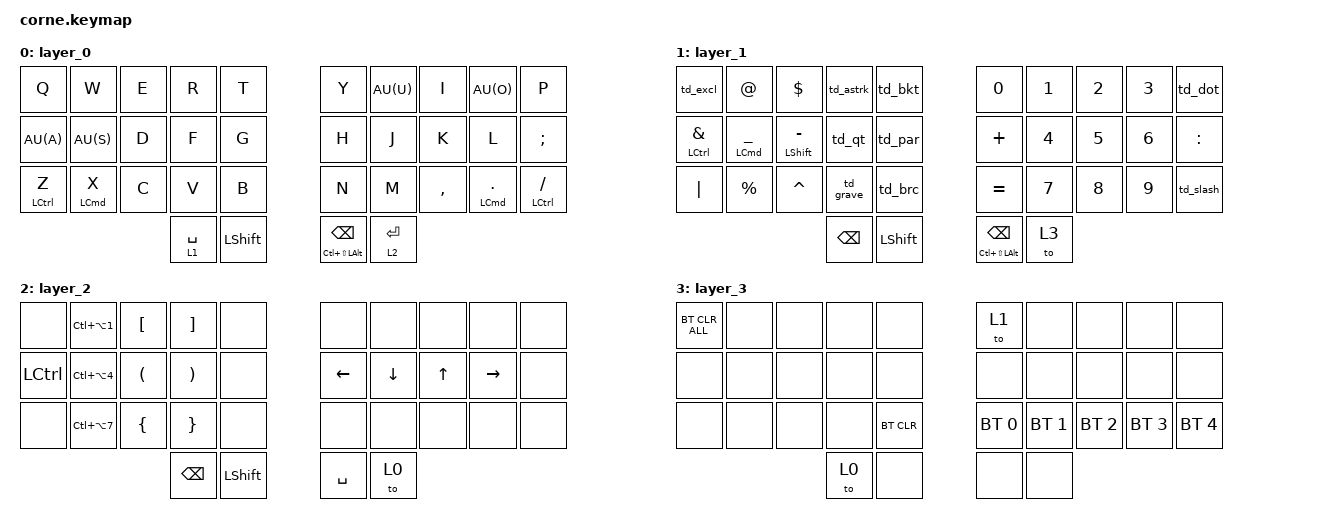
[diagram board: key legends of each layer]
/*
 * Copyright (c) 2020 The ZMK Contributors
 *
 * SPDX-License-Identifier: MIT
 */

#include <behaviors.dtsi>
#include <dt-bindings/zmk/bt.h>
#include <dt-bindings/zmk/keys.h>
#include <dt-bindings/zmk/outputs.h>

#define L0 0
#define L1 1
#define L2 2
#define L3 3
#define L4 4


#define AU(keycode) &au LA(keycode) keycode  // Autoumlauts Macro 


&mt {
	flavor = "tap-preferred";
	tapping_term_ms = <200>;
	quick_tap_ms = <125>;
};


/ {
    macros {
        /**
     * Macro for typing the `!=` combination.
     */

        excl_eq: excl_eq {
            label = "EXCL_EQ";
            compatible = "zmk,behavior-macro";
            #binding-cells = <0>;
            bindings = <&kp EXCL &kp EQUAL>;
        };

    };

    behaviors {
			lm: layer_mod {
				label = "LAYER_MOD";
				compatible = "zmk,behavior-hold-tap";
				flavor = "hold-preferred";
				tapping_term_ms = <200>;
                #binding-cells = <2>;
				bindings = <&kp>,<&to>;
			};

        /**
     * Key press `~` on single tapped or key press ``` on double tapped.
     */

        td_grave: tap_dance_grave {
            compatible = "zmk,behavior-tap-dance";
            label = "TAP_DANCE_GRAVE";
            #binding-cells = <0>;
            tapping-term-ms = <200>;
            bindings =
                <&kp GRAVE>,
                <&kp TILDE>;
        };

        /**
     * Key press `[` on single tap or key press `]` on double tap.
     */

        td_bkt: tap_dance_bkt {
            compatible = "zmk,behavior-tap-dance";
            label = "TAP_DANCE_BKT";
            #binding-cells = <0>;
            tapping-term-ms = <200>;
            bindings =
                <&kp LBKT>,
                <&kp RBKT>;
        };

        /**
     * Key press `(` on single tap or key press `)` on double tap.
     */

        td_par: tap_dance_par {
            compatible = "zmk,behavior-tap-dance";
            label = "TAP_DANCE_PAR";
            #binding-cells = <0>;
            tapping-term-ms = <200>;
            bindings =
                <&kp LPAR>,
                <&kp RPAR>;
        };

        /**
     * Key press `{` on single tap or key press `}` on double tap.
     */

        td_brc: tap_dance_brc {
            compatible = "zmk,behavior-tap-dance";
            label = "TAP_DANCE_BRC";
            #binding-cells = <0>;
            tapping-term-ms = <200>;
            bindings =
                <&kp LBRC>,
                <&kp RBRC>;
        };

        /**
     * Key press `'` on single tap, hold LALT modifier on hold, or key press `"` on double tap.
     */

        td_qt: tap_dance_qt {
            compatible = "zmk,behavior-tap-dance";
            label = "TAP_DANCE_QT";
            #binding-cells = <0>;
            tapping-term-ms = <200>;
            bindings =
                <&hm LALT SQT>,
                <&kp DQT>;
        };

        /**
     * Key press `!` on single tap or macro in `!=` on double tap.
     */

        td_excl: tap_dance_excl {
            compatible = "zmk,behavior-tap-dance";
            label = "TAP_DANCE_EXCL";
            #binding-cells = <0>;
            tapping-term-ms = <200>;
            bindings =
                <&kp EXCL>,
                <&excl_eq>;
        };

        /**
     * Key press `.` on single tap or key press `,` on double tap.
     */

        td_dot: td_dot {
            compatible = "zmk,behavior-tap-dance";
            label = "TAP_DANCE_DOT";
            #binding-cells = <0>;
            tapping-term-ms = <200>;
            bindings =
                <&kp DOT>,
                <&kp COMMA>;
        };

        /**
     * Key press `/` on single tap or key press `\` on double tap.
     */

        td_slash: td_slash {
            compatible = "zmk,behavior-tap-dance";
            label = "TAP_DANCE_SLASH";
            #binding-cells = <0>;
            tapping-term-ms = <200>;
            bindings =
                <&kp SLASH>,
                <&kp BACKSLASH>;
        };

        /**
     * Key press `*` on single tap or key press `#` on double tap.
     */

        td_astrk: td_astrk {
            compatible = "zmk,behavior-tap-dance";
            label = "TAP_DANCE_ASTRK";
            #binding-cells = <0>;
            tapping-term-ms = <200>;
            bindings =
                <&kp ASTRK>,
                <&kp HASH>;
        };

        /**
     * Configuration for hold-tap behavior used for home-row modifiers.
     */

        hm: homerow_mods {
            compatible = "zmk,behavior-hold-tap";
            label = "HOMEROW_MODS";
            #binding-cells = <2>;
            tapping-term-ms = <200>;
            quick-tap-ms = <0>;
            flavor = "balanced";
            bindings =
                <&kp>,
                <&kp>;
        };

        /**
     * Configuration for hold-tap behavior used for umlauts.
     */

        au: auto_umlauts {
            compatible = "zmk,behavior-hold-tap";
            label = "HOMEROW_MODS";
            #binding-cells = <2>;
            tapping-term-ms = <225>;
            quick-tap-ms = <0>;
            flavor = "tap-preferred";
            bindings =
                <&kp>,
                <&kp>;
        };
    };

    combos {
        compatible = "zmk,combos";
        /**
     * Macro for toggling layer 3
     */
		 		layer3 {
            timeout-ms = <50>;
            key-positions = <5 6>;
            bindings = <&to L3>;
				};

        /**
     * Key press `ESC` when keys 12 (D) and 13 (F) are tapped.
     */

        escape_key {
            timeout-ms = <20>;
            key-positions = <12 13>;
            bindings = <&kp ESC>;
        };


        /**
     * Key press `TAB' when keys 17 (K) and 18 (L) are tapped.
     */

        tab_key {
            timeout-ms = <20>;
            key-positions = <17 18>;
            bindings = <&kp TAB>;
        };

        /**
     * Key press `LCTRL + LCMD + Q` (lock screen in macOS) when keys 27 (,) and 28 (.) are tapped.
     *
     * Only enabled for layer 0 (base layer).
     */

        lock_screen {
            timeout-ms = <20>;
            key-positions = <27 28>;
            bindings = <&kp LC(LG(Q))>;
            layers = <0>;
        };

    };

    keymap {
        compatible = "zmk,keymap";

        /**
     * Base layer that contains all characters and writting controls (space and backspace) as well as the most
     * common icons.
     */

				layer_0 {
            bindings = <
       &kp Q       &kp W   &kp E      &kp R      &kp T     &kp Y   AU(U)      &kp I         AU(O)            &kp P
       AU(A)       AU(S)   &kp D      &kp F      &kp G     &kp H   &kp J      &kp K         &kp L       &kp SEMI
 &hm LCTRL Z  &hm LCMD X   &kp C      &kp V      &kp B     &kp N   &kp M  &kp COMMA  &hm LCMD DOT  &hm LCTRL SLASH
                                  &lt 1 SPACE  &kp LSHFT    &mt LC(LS(LALT)) BSPC   &lt 2 ENTER
            >;
        };

/**
     * Icons and numbers layer.
     */
    layer_1 {
      bindings = <
        &td_excl        &kp AT          &kp DOLLAR       &td_astrk  &td_bkt            &kp N0     &kp N1       &kp N2        &kp N3       &td_dot
        &hm LCTRL AMPS  &hm LCMD UNDER  &hm LSHFT MINUS  &td_qt     &td_par            &kp PLUS   &kp N4       &kp N5        &kp N6       &kp COLON
        &kp PIPE        &kp PRCNT       &kp CARET        &td_grave  &td_brc            &kp EQUAL  &kp N7       &kp N8        &kp N9       &td_slash
                                                         &kp BSPC   &kp LSHFT          &mt LC(LS(LALT)) BSPC   &to L3
      >;
    };


   /**
     * Controls layer that contains OS controls (bluetooth, mute, play, etc.) and modifiers.
     */
    layer_2 {
      bindings = <
        &none       &kp LC(LA(N1))  &kp LBKT  &kp RBKT  &none            &none      &none         &none       &none         &none
        &kp LCTRL   &kp LC(LA(N4))  &kp LPAR  &kp RPAR  &none            &kp LEFT   &kp DOWN      &kp UP      &kp RIGHT     &none
        &none       &kp LC(LA(N7))  &kp LBRC  &kp RBRC  &none            &none      &none         &none       &none         &none
											&kp BSPC    &kp LSHFT        &kp SPACE     &to L0
      >;
    };

        /**
     * Controls layer that contains OS controls (bluetooth, mute, play, etc.) and modifiers.
     */

        layer_3 {
            bindings = <
        &bt BT_CLR_ALL  &none           &none           &none               &none               &to 1               &none           &none           &none               &none
        &none           &none           &none           &none               &none               &none               &none           &none           &none               &none
        &none           &none           &none           &none               &bt BT_CLR          &bt BT_SEL 0        &bt BT_SEL 1    &bt BT_SEL 2    &bt BT_SEL 3        &bt BT_SEL 4
                                                        &to L0              &none               &none               &none
            >;
        };
    };
};


